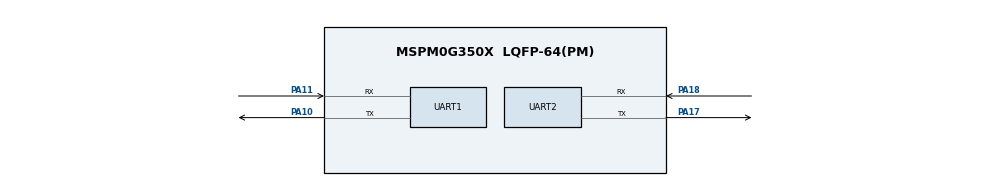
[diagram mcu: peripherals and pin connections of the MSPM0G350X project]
/**
 * @cliArgs --device "MSPM0G350X" --part "Default" --package "LQFP-64(PM)" --product "mspm0_sdk@2.06.00.05"
 * @versions {"tool":"1.21.0+3721"}
 */

/**
 * Import the modules used in this configuration.
 */
const GPIO   = scripting.addModule("/ti/driverlib/GPIO", {}, false);
const GPIO1  = GPIO.addInstance();
const GPIO2  = GPIO.addInstance();
const GPIO3  = GPIO.addInstance();
const GPIO4  = GPIO.addInstance();
const SYSCTL = scripting.addModule("/ti/driverlib/SYSCTL");
const UART   = scripting.addModule("/ti/driverlib/UART", {}, false);
const UART1  = UART.addInstance();
const UART2  = UART.addInstance();

/**
 * Write custom configuration values to the imported modules.
 */
GPIO1.$name                          = "GPIO_LED";
GPIO1.associatedPins[0].$name        = "PIN_0";
GPIO1.associatedPins[0].assignedPort = "PORTB";
GPIO1.associatedPins[0].assignedPin  = "14";

const Board = scripting.addModule("/ti/driverlib/Board", {}, false);

GPIO2.$name                          = "MPU6500";
GPIO2.associatedPins.create(2);
GPIO2.associatedPins[0].$name        = "SCL";
GPIO2.associatedPins[0].assignedPort = "PORTA";
GPIO2.associatedPins[0].initialValue = "SET";
GPIO2.associatedPins[0].assignedPin  = "31";
GPIO2.associatedPins[1].$name        = "SDA";
GPIO2.associatedPins[1].assignedPort = "PORTA";
GPIO2.associatedPins[1].initialValue = "SET";
GPIO2.associatedPins[1].assignedPin  = "28";

GPIO3.$name                              = "GPIO_PIN";
GPIO3.associatedPins[0].$name            = "PIN_1";
GPIO3.associatedPins[0].direction        = "INPUT";
GPIO3.associatedPins[0].internalResistor = "PULL_UP";
GPIO3.associatedPins[0].interruptEn      = true;
GPIO3.associatedPins[0].polarity         = "FALL";
GPIO3.associatedPins[0].assignedPort     = "PORTB";
GPIO3.associatedPins[0].assignedPin      = "8";

GPIO4.$name                          = "GPIO_buzzer";
GPIO4.associatedPins[0].$name        = "PIN_2";
GPIO4.associatedPins[0].assignedPort = "PORTB";
GPIO4.associatedPins[0].assignedPin  = "7";

SYSCTL.forceDefaultClkConfig = true;

UART1.$name                    = "UART_0";
UART1.targetBaudRate           = 115200;
UART1.peripheral.rxPin.$assign = "PA11";
UART1.peripheral.txPin.$assign = "PA10";
UART1.txPinConfig.$name        = "ti_driverlib_gpio_GPIOPinGeneric0";
UART1.rxPinConfig.$name        = "ti_driverlib_gpio_GPIOPinGeneric1";

UART2.$name                            = "UART_4g";
UART2.targetBaudRate                   = 115200;
UART2.peripheral.$assign               = "UART1";
UART2.peripheral.rxPin.$assign         = "PA18";
UART2.peripheral.txPin.$assign         = "PA17";
UART2.txPinConfig.$name                = "ti_driverlib_gpio_GPIOPinGeneric2";
UART2.txPinConfig.direction            = scripting.forceWrite("OUTPUT");
UART2.txPinConfig.hideOutputInversion  = scripting.forceWrite(false);
UART2.txPinConfig.onlyInternalResistor = scripting.forceWrite(false);
UART2.txPinConfig.passedPeripheralType = scripting.forceWrite("Digital");
UART2.rxPinConfig.$name                = "ti_driverlib_gpio_GPIOPinGeneric3";
UART2.rxPinConfig.hideOutputInversion  = scripting.forceWrite(false);
UART2.rxPinConfig.onlyInternalResistor = scripting.forceWrite(false);
UART2.rxPinConfig.passedPeripheralType = scripting.forceWrite("Digital");

/**
 * Pinmux solution for unlocked pins/peripherals. This ensures that minor changes to the automatic solver in a future
 * version of the tool will not impact the pinmux you originally saw.  These lines can be completely deleted in order to
 * re-solve from scratch.
 */
GPIO1.associatedPins[0].pin.$suggestSolution = "PB14";
Board.peripheral.$suggestSolution            = "DEBUGSS";
Board.peripheral.swclkPin.$suggestSolution   = "PA20";
Board.peripheral.swdioPin.$suggestSolution   = "PA19";
GPIO2.associatedPins[0].pin.$suggestSolution = "PA31";
GPIO2.associatedPins[1].pin.$suggestSolution = "PA28";
GPIO3.associatedPins[0].pin.$suggestSolution = "PB8";
GPIO4.associatedPins[0].pin.$suggestSolution = "PB7";
SYSCTL.peripheral.$suggestSolution           = "SYSCTL";
UART1.peripheral.$suggestSolution            = "UART0";
